# STM32H573 register map
File version: 1.7
CPU: CM33 r0p0, little endian, MPU, FPU, 4 interrupt priority bits
Registers are 32-bit, read-write, reset 0x0 unless marked. A register's access mark holds for its fields unless they carry their own. Offsets are from the block's base; [hi:lo] are bit positions; lines under a group give offsets from that group; {n}, {i} and the like mark numbered series; 'fields as' and 'values as' point back to an identical list.

## FLASH (part 2 of 2) — FLASH address block description
Base 0x40022000
Same registers: SEC_FLASH 0x50022000
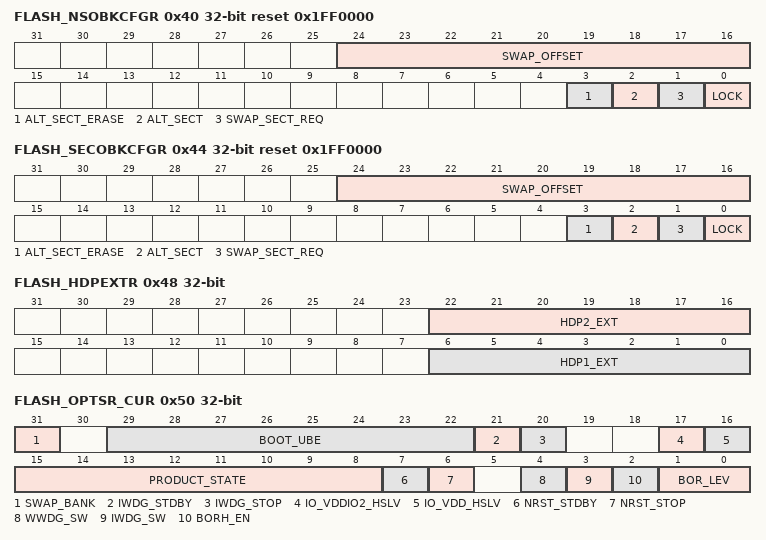
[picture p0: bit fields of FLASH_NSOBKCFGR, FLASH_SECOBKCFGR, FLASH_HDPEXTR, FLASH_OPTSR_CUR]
0x40 FLASH_NSOBKCFGR reset 0x1FF0000 — FLASH non-secure OBK configuration register
  [24:16] SWAP_OFFSET — Key index (offset /16 bits) pointing for next swap. 0x01 means that only the first OBK data (128 bits) is copied from current to alternate OBK sector 0x02 means that the two first OBK data is copied
    0=means that no OBK is copied from current to alternate OBK sector during SWAP operation; 0x1FF=means that all OBK data (511) is copied
  [3] ALT_SECT_ERASE — alternate sector erase bit When ALT_SECT bit is set, use this bit to generate an erase command for the OBK alternate sector. It is set only by Software and cleared when the OBK swap operation is completed or an error occurs (PGSERR). It is reseted at the same time as BUSY bit.
    0=do not touch OBK sector; 1=erase the alternate OBK sector
  [2] ALT_SECT — alternate sector bit This bit must not change while filling the write buffer, otherwise an error (OBKERR) is generated
    0=current OBK sector is mapped to OBK address range for access; 1=alternate OBK sector is mapped to OBK address range for access
  [1] SWAP_SECT_REQ — OBK swap sector request bit When set, all the OBKs which have not been updated in the alternate sector is copied from current sector to alternate one. The SWAP_OFFSET value must be a certain minimum value in order for the swap to be launched in OBK-HDPLdifferent 0. Minimum value is 16 for OBK-HDPL=1, 144 for OBK-HDPL=2 and192 for OBK-HDPL=3.
    0=no swap requested; 1=launch the sector swap
  [0] LOCK — OBKCFGR lock option configuration bit This bit locks the FLASH_NSOBKCFGR register. The correct write sequence to FLASH_NSOBKKEYR register unlocks this bit. If a wrong sequence is executed, or if the unlock sequence to FLASH_NSOBKKEYR is performed twice, this bit remains locked until the next system reset. LOCK can be set by programming it to 1. When set to 1, a new unlock sequence is mandatory to unlock it. When LOCK changes from 0 to 1, the other bits of FLASH_NSCR register do not change.
    0=FLASH_NSOBKCFGR register unlocked; 1=FLASH_NSOBKCFGR register locked
0x44 FLASH_SECOBKCFGR reset 0x1FF0000 — FLASH secure OBK configuration register
  [24:16] SWAP_OFFSET — key index (offset /16 bits) pointing for next swap.
    0=no OBK is copied from current to alternate OBK sector during SWAP operation; 1=only the first OBK data (128 bits) is copied from current to alternate OBK sector; 2=the two first OBK data are copied; 0x1FF=that the 511 first OBK data are copied
  [3] ALT_SECT_ERASE — alternate sector erase bit When ALT_SECT bit is set, use this bit to generate an erase command for the OBK alternate sector. It is set only by Software and cleared when the OBK swap operation is completed or an error occurs (PGSERR). It is reseted at the same time as the BUSY bit.
    0=do not touch OBK sector; 1=erase the alternate OBK sector
  [2] ALT_SECT — alternate sector bit This bit must not change while filling the write buffer, otherwise an error is generated
    values as FLASH_NSOBKCFGR.ALT_SECT
  [1] SWAP_SECT_REQ — OBK swap sector request bit When set, all the OBKs which have not been updated in the alternate sector is copied from current sector to alternate one. The SWAP_OFFSET value must be a certain minimum value in order for the swap to be launched in OBK-HDPLdifferent 0. Minimum value is 16 for OBK-HDPL=1, 144 for OBK-HDPL=2 and 192 for OBK-HDPL=3.
    0=no swap requested; 1=launch the sector swap
  [0] LOCK — OBKCFGR lock option configuration bit This bit locks the FLASH_OBKCFGR register. The correct write sequence to FLASH_SECOBKKEYR register unlocks this bit. If a wrong sequence is executed, or if the unlock sequence to FLASH_SECOBKKEYR is performed twice, this bit remains locked until the next system reset. LOCK can be set by programming it to 1. When set to 1, a new unlock sequence is mandatory to unlock it. When LOCK changes from 0 to 1, the other bits of FLASH_NSCR register do not change.
    0=FLASH_OBKCFGR register unlocked; 1=FLASH_OBKCFGR register locked
0x48 FLASH_HDPEXTR — FLASH HDP extension register
  [22:16] HDP2_EXT — HDP area extension in 8Kbytes sectors in bank 2. Extension is added after the HDP2_END sector (included).
  [6:0] HDP1_EXT — HDP area extension in 8Kbytes sectors in Bank1. Extension is added after the HDP1_END sector (included).
0x50 FLASH_OPTSR_CUR ro reset not defined — FLASH option status register
  [31] SWAP_BANK — Bank swapping option status bit SWAP_BANK reflects whether Bank1 and Bank2 are swapped or not. SWAP_BANK is loaded to SWAP_BANK of FLASH_OPTCR after a reset.
    0=Bank1 and Bank2 not swapped; 1=Bank1 and Bank2 swapped
  [29:22] BOOT_UBE — Available only on cryptography enabled devices. Unique boot entry control, selects either ST or OEM iRoT for secure boot.
    195=ST-iRoT (system flash) selected; 180=OEM-iRoT (user flash) selected. In Open PRODUCT_STATE this value selects bootloader. Defaut value.
  [21] IWDG_STDBY — IWDG Standby mode freeze option status bit When set the independent watchdog IWDG is frozen in system Standby mode.
    0=Independent watchdog frozen in Standby mode; 1=Independent watchdog keep running in Standby mode
  [20] IWDG_STOP — IWDG Stop mode freeze option status bit When set the independent watchdog IWDG is in system Stop mode.
    0=Independent watchdog frozen in system Stop mode; 1=Independent watchdog keep running in system Stop mode
  [17] IO_VDDIO2_HSLV — High-speed IO at low V sub DDIO2 /sub voltage configuration bit. This bit can be set only with V sub DDIO2 /sub below 2.7V.
    0=High-speed IO at low V sub DDIO2 /sub voltage feature disabled (V sub DDIO2 /sub can exceed 2.7V); 1=High-speed IO at low V sub DDIO2 /sub voltage feature enabled (V sub DDIO2 /sub remains below 2.7V)
  [16] IO_VDD_HSLV — High-speed IO at low V sub DD /sub voltage configuration bit. This bit can be set only with V sub DD /sub below 2.7V.
    0=High-speed IO at low V sub DD /sub voltage feature disabled (V sub DD /sub can exceed 2.7V); 1=High-speed IO at low V sub DD /sub voltage feature enabled (V sub DD /sub remains below 2.7V)
  [15:8] PRODUCT_STATE — Life state code (based on Hamming 8,4). More information in Section7.6.11: Product state transitions.
  [7] NRST_STDBY — Core domain Standby entry reset option status bit
    0=a reset is generated when entering Standby mode on core domain; 1=no reset generated when entering Standby mode on core domain
  [6] NRST_STOP — Core domain Stop entry reset option status bit
    0=a reset is generated when entering Stop mode on core domain; 1=no reset generated when entering Stop mode on core domain
  [4] WWDG_SW — WWDG control mode option status bit
    0=WWDG watchdog is controlled by hardware; 1=WWDG watchdog is controlled by software
  [3] IWDG_SW — IWDG control mode option status bit
    0=IWDG watchdog is controlled by hardware; 1=IWDG watchdog is controlled by software
  [2] BORH_EN — Brownout high enable
    0=disable; 1=enable
  [1:0] BOR_LEV — Brownout level option status bit These bits reflects the power level that generates a system reset. 00 or 11: BOR Level 1, the threshold level is low (around 2.1V)
    1=BOR Level 2, the threshold level is medium (around 2.4V); 2=BOR Level 3, the threshold level is high (around 2.7V)
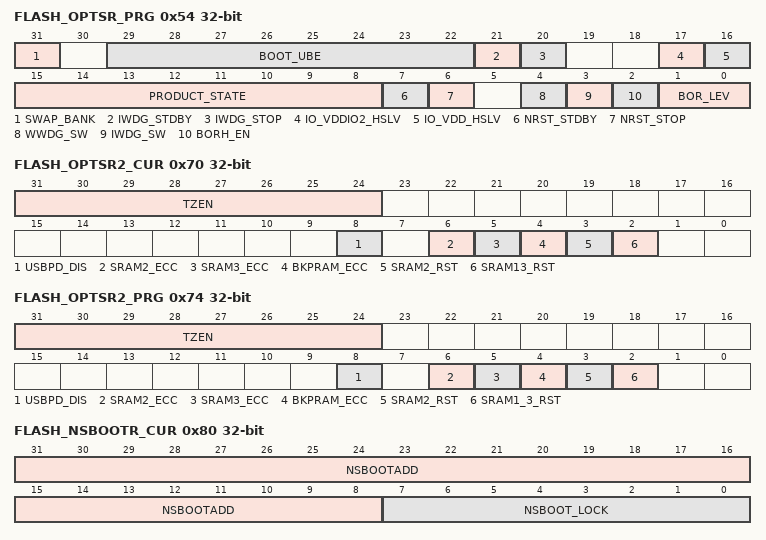
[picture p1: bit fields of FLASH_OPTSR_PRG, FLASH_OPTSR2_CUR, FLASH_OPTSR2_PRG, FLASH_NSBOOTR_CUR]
0x54 FLASH_OPTSR_PRG reset not defined — FLASH option status register
  [31] SWAP_BANK — Bank swapping option configuration bit SWAP_BANK option bit is used to configure whether the Bank1 and Bank2 are swapped or not. This bit is loaded with the SWAP_BANK bit of FLASH_OPTSR_CUR register after a reset.
    0=Bank1 and Bank2 not swapped; 1=Bank1 and Bank2 swapped
  [29:22] BOOT_UBE — Available only on cryptography enabled devices. Unique boot entry control, selects either ST or OEM iRoT for secure boot. In Open PRODUCT_STATE this value selects bootloader. Defaut value.
    195=ST-iRoT (system flash) selected; 180=OEM-iRoT (user flash) selected
  [21] IWDG_STDBY — IWDG Standby mode freeze option status bit When set the independent watchdog IWDG is frozen in system Standby mode.
    values as FLASH_OPTSR_CUR.IWDG_STDBY
  [20] IWDG_STOP — IWDG Stop mode freeze option status bit When set the independent watchdog IWDG is in system Stop mode.
    values as FLASH_OPTSR_CUR.IWDG_STOP
  [17] IO_VDDIO2_HSLV — High-speed IO at low VDDIO2 voltage configuration bit. This bit can be set only with VDDIO2 below 2.7V.
    0=High-speed IO at low VDDIO2 voltage feature disabled (VDDIO2 can exceed 2.7V); 1=High-speed IO at low VDDIO2 voltage feature enabled (VDDIO2 remains below 2.7V)
  [16] IO_VDD_HSLV — High-speed IO at low VDD voltage configuration bit. This bit can be set only with VDD below 2.7V.
    0=High-speed IO at low VDD voltage feature disabled (VDD can exceed 2.7V); 1=High-speed IO at low VDD voltage feature enabled (VDD remains below 2.7V)
  [15:8] PRODUCT_STATE — Life state code (based on Hamming 8,4). More information in Section7.6.11: Product state transitions.
  [7] NRST_STDBY — Core domain Standby entry reset option configuration bit
    values as FLASH_OPTSR_CUR.NRST_STDBY
  [6] NRST_STOP — Core domain Stop entry reset option configuration bit
    values as FLASH_OPTSR_CUR.NRST_STOP
  [4] WWDG_SW — WWDG control mode option configuration bit
    values as FLASH_OPTSR_CUR.WWDG_SW
  [3] IWDG_SW — IWDG control mode option configuration bit
    values as FLASH_OPTSR_CUR.IWDG_SW
  [2] BORH_EN — Brownout high enable configuration bit
    0=disable; 1=enable
  [1:0] BOR_LEV — Brownout level option configuration bit These bits reflects the power level that generates a system reset. 00 or 11: BOR Level 1, the threshold level is low (around 2.1 V)
    1=BOR Level 2, the threshold level is medium (around 2.4 V); 2=BOR Level 3, the threshold level is high (around 2.7 V)
0x60 FLASH_NSEPOCHR_CUR ro reset not defined — FLASH non-secure EPOCH register
  [23:0] NS_EPOCH — Non-volatile non-secure EPOCH counter
0x68 FLASH_SECEPOCHR_CUR ro reset not defined — FLASH secure EPOCH register
  [23:0] SEC_EPOCH — Non-volatile secure EPOCH counter
0x70 FLASH_OPTSR2_CUR ro reset not defined — FLASH option status register 2
  [31:24] TZEN — TrustZone enable configuration bits This bit enables the device is in TrustZone mode during an option byte change.
    195=TrustZone disabled; 180=TrustZone enabled
  [8] USBPD_DIS — USB power delivery configuration option bit
    0=Enabled; 1=Disabled
  [6] SRAM2_ECC — SRAM2 ECC detection and correction disable
    0=SRAM2 ECC check enabled; 1=SRAM2 ECC check disabled
  [5] SRAM3_ECC — SRAM3 ECC detection and correction disable
    0=SRAM3 ECC check enabled; 1=SRAM3 ECC check disabled
  [4] BKPRAM_ECC — Backup RAM ECC detection and correction disable
    0=BKPRAM ECC check enabled; 1=BKPRAM ECC check disabled
  [3] SRAM2_RST — SRAM2 erase when system reset
    0=SRAM2 erased when a system reset occurs; 1=SRAM2 not erased when a system reset occurs
  [2] SRAM13_RST — SRAM1 and SRAM3 erase upon system reset
    0=SRAM1 and SRAM3 erased when a system reset occurs; 1=SRAM1 and SRAM3 not erased when a system reset occurs
0x74 FLASH_OPTSR2_PRG reset not defined — FLASH option status register 2
  [31:24] TZEN — TrustZone enable configuration bits This bit enables the device is in TrustZone mode during an option byte change.
    195=TrustZone disabled; 180=TrustZone enabled
  [8] USBPD_DIS — USB power delivery configuration option bit
    0=Enabled; 1=Disabled
  [6] SRAM2_ECC — SRAM2 ECC detection and correction disable
    0=SRAM2 ECC check enabled; 1=SRAM2 ECC check disabled
  [5] SRAM3_ECC — SRAM3 ECC detection and correction disable
    0=SRAM3 ECC check enabled; 1=SRAM3 ECC check disabled
  [4] BKPRAM_ECC — Backup RAM ECC detection and correction disable
    0=BKPRAM ECC check enabled; 1=BKPRAM ECC check disabled
  [3] SRAM2_RST — SRAM2 erase when system reset Note: SRAM erase is triggered by option byte change operation, when enabling this feature.
    values as FLASH_OPTSR2_CUR.SRAM2_RST
  [2] SRAM1_3_RST — SRAM1 and SRAM3 erase upon system reset Note: SRAM erase is triggered by option byte change operation, when enabling this feature.
    values as FLASH_OPTSR2_CUR.SRAM13_RST
0x80 FLASH_NSBOOTR_CUR ro reset not defined — FLASH non-secure boot register
  [31:8] NSBOOTADD — Non secure unique boot entry address These bits reflect the Non secure UBE address
  [7:0] NSBOOT_LOCK — A field locking the values of SWAP_BANK, and NSBOOTADD settings.
    195=The SWAP_BANK and NSBOOTADD can still be modified following their individual rules; 180=The NSBOOTADD is frozen. SWAP_ BANK can only be modified with TZEN set to 0xB4 (enabled).
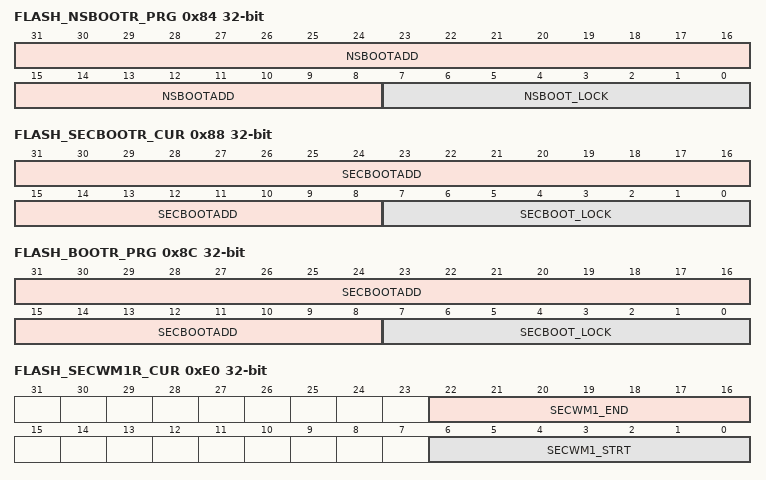
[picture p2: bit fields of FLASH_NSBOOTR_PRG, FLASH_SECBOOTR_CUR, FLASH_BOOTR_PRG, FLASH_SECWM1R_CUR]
0x84 FLASH_NSBOOTR_PRG reset not defined — FLASH non-secure boot register
  [31:8] NSBOOTADD — Non secure unique boot entry address These bits allow configuring the Non secure BOOT address
  [7:0] NSBOOT_LOCK — A field locking the values of SWAP_ BANK, and NSBOOTADD settings.
    195=The SWAP_ BANK and NSBOOTADD can still be modified following their individual rules; 180=The NSBOOTADD is frozen. SWAP_ BANK can only be modified with TZEN set to 0xB4 (enabled).
0x88 FLASH_SECBOOTR_CUR ro reset not defined — FLASH secure boot register
  [31:8] SECBOOTADD — Unique boot entry secure address These bits reflect the Secure UBE address
  [7:0] SECBOOT_LOCK — A field locking the values of UBE, SWAP_BANK, and SECBOOTADD settings.
    195=The BOOT_UBE, SWAP_BANK and SECBOOTADD can still be modified following their individual rules; 180=The BOOT_UBE and SECBOOTADD are frozen. SWAP_ BANK can only be modified with TZEN set to 0xC3 (disabled).
0x8C FLASH_BOOTR_PRG reset not defined — FLASH secure boot register
  [31:8] SECBOOTADD — Secure unique boot entry address. These bits allow configuring the secure UBE address.
  [7:0] SECBOOT_LOCK — A field locking the values of UBE, SWAP_ BANK, and SECBOOTADD setting.
    195=The BOOT_UBE, SWAP_ BANK and SECBOOTADD can still be modified following their individual rules; 180=The BOOT_UBE and SECBOOTADD are frozen. SWAP_BANK can only be modified with TZEN set to 0xC3 (disabled).
0x90 FLASH_OTPBLR_CUR ro reset not defined — FLASH non-secure OTP block lock
  [31:0] LOCKBL — OTP block lock Block n corresponds to OTP 16-bit word 32 x n to 32 x n + 31. LOCKBL[n] = 1 indicates that all OTP 16-bit words in OTP Block n are locked and attempt to program them results in WRPERR. LOCKBL[n] = 0 indicates that all OTP 16-bit words in OTP Block n are not locked. When one block is locked, it's not possible to remove the write protection. Also if not locked, it is not possible to erase OTP words.
0x94 FLASH_OTPBLR_PRG reset not defined — FLASH non-secure OTP block lock
  [31:0] LOCKBL — OTP block lock Block n corresponds to OTP 16-bit word 32 x n to 32 x n + 31. LOCKBL[n] = 1 indicates that all OTP 16-bit words in OTP Block n are locked and attempt to program them results in WRPERR. LOCKBL[n] = 0 indicates that all OTP 16-bit words in OTP Block n are not locked. When one block is locked, it is not possible to remove the write protection. LOCKBL bits can be set if the corresponding bit in FLASH_OTPBLR_CUR is cleared.
{0x9C+4i} FLASH_SECBB1R{i} (i=1..4) — FLASH secure block based register for Bank 1
  [31:0] SECBB1 — Secure/non-secure 8Kbytes flash Bank 1 sector attributes
    0=sector (32 * (x-1) + y) in bank 1 is non secure; 1=sector (32 * (x-1) + y) in bank 1 is secure
{0xBC+4i} FLASH_PRIVBB1R{i} (i=1..4) — FLASH privilege block based register for Bank 1
  [31:0] PRIVBB1 — Privileged/unprivileged 8-Kbyte flash Bank 1 sector attribute
    0=sectors (32 * (x-1) + y) in bank 1 is unprivileged; 1=sector (32 * (x-1) + y) in bank 1 is privileged
0xE0 FLASH_SECWM1R_CUR ro (reset mask 0xFF00FF00) — FLASH security watermark for Bank 1
  [22:16] SECWM1_END — Bank1 security WM area 1 end sector
  [6:0] SECWM1_STRT — Bank1 security WM area 1 start sector
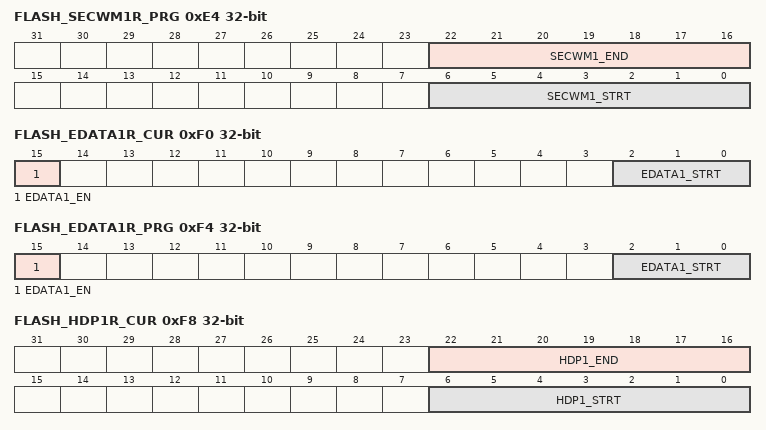
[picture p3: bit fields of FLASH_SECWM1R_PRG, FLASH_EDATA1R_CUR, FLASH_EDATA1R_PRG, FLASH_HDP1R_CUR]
0xE4 FLASH_SECWM1R_PRG (reset mask 0xFF00FF00) — FLASH security watermark for Bank 1
  fields as FLASH_SECWM1R_CUR
0xE8 FLASH_WRP1R_CUR ro reset not defined — FLASH write sector group protection for Bank 1
  [31:0] WRPSG1 — Bank 1 sector group protection option status byte Each FLASH_WRP1R_CUR bit reflects the write protection status of the corresponding group of four consecutive sectors in bank 1 (0: the group is write protected; 1: the group is not write protected) Bit 0: Group embedding sectors 0 to 3 Bit 1: Group embedding sectors 4 to 7 Bit N: Group embedding sectors 4 x N to 4 x N + 3 Bit 31: Group embedding sectors 124 to 127
0xEC FLASH_WRP1R_PRG reset not defined — FLASH write sector group protection for Bank 1
  [31:0] WRPSG1 — Bank1 sector group protection option status byte Setting WRPSG1 bits to 0 write protects the corresponding group of four consecutive sectors in bank 1 (0: the group is write protected; 1: the group is not write protected) Bit 0: Group embedding sectors 0 to 3 Bit 1: Group embedding sectors 4 to 7 Bit N: Group embedding sectors 4 x N to 4 x N + 3 Bit 31: Group embedding sectors 124 to 127
0xF0 FLASH_EDATA1R_CUR ro reset not defined — FLASH data sector configuration Bank 1
  [15] EDATA1_EN — Bank1 flash high-cycle data enable
    0=No flash high-cycle data area; 1=Flash high-cycle data is used
  [2:0] EDATA1_STRT — EDATA1_STRT contains the start sectors of the flash high-cycle data area in Bank1 There is no hardware effect to those bits. They shall be managed by ST tools in Flasher. ...
    0=The last sector of the Bank1 is reserved for flash high-cycle data; 1=The two last sectors of the Bank 1 are reserved for flash high-cycle data; 2=The three last sectors of the Bank 1 are reserved for flash high-cycle data; 7=The eight last sectors of the Bank 1 are reserved for flash high-cycle data
0xF4 FLASH_EDATA1R_PRG reset not defined — FLASH data sector configuration Bank 1
  [15] EDATA1_EN — Bank 1 flash high-cycle data enable
    values as FLASH_EDATA1R_CUR.EDATA1_EN
  [2:0] EDATA1_STRT — EDATA1_STRT contains the start sectors of the flash high-cycle data area in Bank 1 There is no hardware effect to those bits. They shall be managed by ST tools in Flasher. ... Note: 111: The eight last sectors of the Bank 1 are reserved for flash high-cycle data
    0=The last sector of the Bank 1 is reserved for flash high-cycle data; 1=The two last sectors of the Bank 1 are reserved for flash high-cycle data; 2=The three last sectors of the Bank 1 are reserved for flash high-cycle data
0xF8 FLASH_HDP1R_CUR ro reset not defined — FLASH HDP Bank 1 configuration
  [22:16] HDP1_END — HDPL barrier end set in number of 8-Kbyte sectors
  [6:0] HDP1_STRT — HDPL barrier start set in number of 8-Kbyte sectors
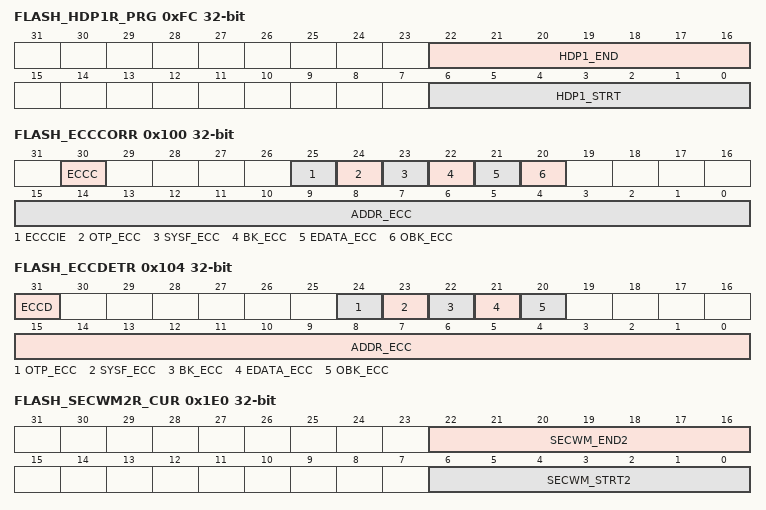
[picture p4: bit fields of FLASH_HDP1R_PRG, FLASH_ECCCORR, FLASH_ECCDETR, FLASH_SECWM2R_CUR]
0xFC FLASH_HDP1R_PRG reset not defined — FLASH HDP Bank 1 configuration
  fields as FLASH_HDP1R_CUR
0x100 FLASH_ECCCORR access per field — FLASH ECC correction register
  [30] ECCC rw — ECC correction set by hardware when single ECC error has been detected and corrected. Cleared by writing 1.
  [25] ECCCIE rw — ECC single correction error interrupt enable bit When ECCCIE bit is set to 1, an interrupt is generated when an ECC single correction error occurs during a read operation.
    0=no interrupt generated when an ECC single correction error occurs; 1=non-secure interrupt generated when an ECC single correction error occurs
  [24] OTP_ECC ro — OTP ECC error bit This bit is set to 1 when one single ECC correction occurred during the last successful read operation from the read-only/ OTP area. The address of the ECC error is available in ADDR_ECC bitfield.
  [23] SYSF_ECC ro — ECC fail for corrected ECC error in system flash memory It indicates if system flash memory is concerned by ECC error.
  [22] BK_ECC ro — ECC fail bank for corrected ECC error It indicates which bank is concerned by ECC error
  [21] EDATA_ECC ro — ECC fail for corrected ECC error in flash high-cycle data area It indicates if flash high-cycle data area is concerned by ECC error.
  [20] OBK_ECC ro — Single ECC error corrected in flash OB Keys storage area. It indicates the OBK storage concerned by ECC error.
  [15:0] ADDR_ECC ro — ECC error address When an ECC error occurs (for single correction) during a read operation, the ADDR_ECC contains the address that generated the error. ADDR_ECC is reset when the flag error is reset. The flash interface programs the address in this register only when no ECC error flags are set. This means that only the first address that generated an ECC error is saved. The address in ADDR_ECC is relative to the flash memory area where the error occurred (user flash memory, system flash memory, data area, read-only/OTP area).
0x104 FLASH_ECCDETR access per field — FLASH ECC detection register
  [31] ECCD rw — ECC detection Set by hardware when two ECC error has been detected. When this bit is set, a NMI is generated. Cleared by writing 1. Needs to be cleared in order to detect subsequent double ECC errors.
  [24] OTP_ECC ro — OTP ECC error bit This bit is set to 1 when double ECC detection occurred during the last read operation from the read-only/ OTP area. The address of the ECC error is available in ADDR_ECC bitfield.
  [23] SYSF_ECC ro — ECC fail for double ECC error in system flash memory It indicates if system flash memory is concerned by ECC error.
  [22] BK_ECC ro — ECC fail bank for double ECC error It indicates which bank is concerned by ECC error
  [21] EDATA_ECC ro — ECC fail double ECC error in flash high-cycle data area It indicates if flash high-cycle data area is concerned by ECC error.
  [20] OBK_ECC ro — ECC fail double ECC error in flash OB Keys storage area. It indicates the OBK storage concerned by ECC error.
  [15:0] ADDR_ECC ro — ECC error address When an ECC error occurs (double detection) during a read operation, the ADDR_ECC contains the address that generated the error. ADDR_ECC is reset when the flag error is reset. The flash interface programs the address in this register only when no ECC error flags are set. This means that only the first address that generated an double ECC error is saved. The address in ADDR_ECC is relative to the flash memory area where the error occurred (user flash memory, system flash memory, data area, read-only/OTP area).
0x108 FLASH_ECCDR ro — FLASH ECC data
  [15:0] DATA_ECC — ECC error data When an double detection ECC error occurs on special areas with 6-bit ECC on 16-bit data (data area, read-only/OTP area), the failing data is read to this register. By checking if it is possible to determine whether the failure was on a real data, or due to access to uninitialized memory.
{0x19C+4i} FLASH_SECBB2R{i} (i=1..4) — FLASH secure block-based register for Bank 2
  [31:0] SECBB2 — Secure/non-secure flash Bank 2 sector attribute
    0=sectors (32 * (x-1) + y) in bank 2 is non secure; 1=sector (32 * (x-1) + y) in bank 2 is secure
{0x1BC+4i} FLASH_PRIVBB2R{i} (i=1..4) — FLASH privilege block-based register for Bank 2
  [31:0] PRIVBB2 — Privileged / non-privileged 8-Kbyte flash Bank 2 sector attribute
    0=sectors (32 * (x-1) + y) in bank 2 is unprivileged; 1=sector (32 * (x-1) + y) in bank 2 is privileged
0x1E0 FLASH_SECWM2R_CUR ro (reset mask 0xFF00FF00) — FLASH security watermark for Bank 2
  [22:16] SECWM_END2 — Bank2 security WM end sector
  [6:0] SECWM_STRT2 — Bank2 security WM area start sector
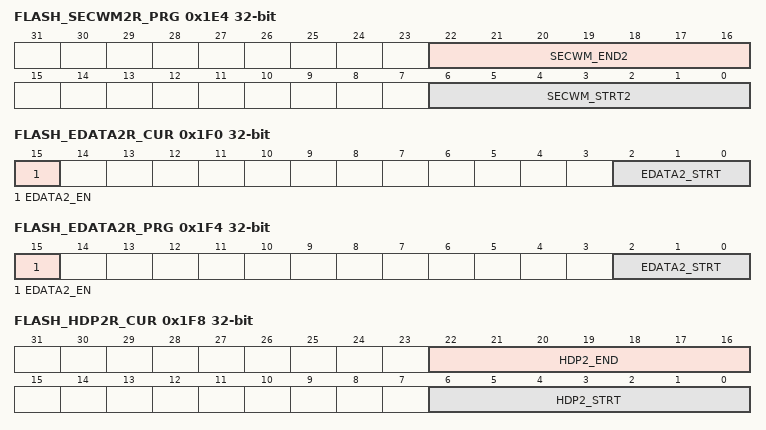
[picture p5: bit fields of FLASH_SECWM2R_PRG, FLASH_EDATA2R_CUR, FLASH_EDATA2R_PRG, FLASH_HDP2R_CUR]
0x1E4 FLASH_SECWM2R_PRG (reset mask 0xFF00FF00) — FLASH security watermark for Bank 2
  [22:16] SECWM_END2 — Bank 2 security WM area end sector
  [6:0] SECWM_STRT2 — Bank 2 security WM area start sector
0x1E8 FLASH_WRP2R_CUR ro reset not defined — FLASH write sector group protection for Bank 2
  [31:0] WRPSG2 — Bank2 sector group protection option status byte Each FLASH_WRP2R_CUR bit reflects the write protection status of the corresponding group of 4 consecutive sectors in bank 2 (0: group is write protected; 1: group is not write protected) Bit 0: Group embedding sectors 0 to 3 Bit 1: Group embedding sectors 4 to 7 Bit N: Group embedding sectors 4 x N to 4 x N + 3 Bit 31: Group embedding sectors 124 to 127
0x1EC FLASH_WRP2R_PRG reset not defined — FLASH write sector group protection for Bank 2
  [31:0] WRPSG2 — Bank 2 sector group protection option status byte Setting WRPSGn2 bits to 0 write protects the corresponding group of four consecutive sectors in Bank 2 (0: group is write protected; 1: group is not write protected) Bit 0: Group embedding sectors 0 to 3 Bit 1: Group embedding sectors 4 to 7 Bit N: Group embedding sectors 4 x N to 4 x N + 3 Bit 31: Group embedding sectors 124 to 127
0x1F0 FLASH_EDATA2R_CUR ro reset not defined — FLASH data sectors configuration Bank 2
  [15] EDATA2_EN — Bank2 flash high-cycle data enable
    values as FLASH_EDATA1R_CUR.EDATA1_EN
  [2:0] EDATA2_STRT — EDATA2_STRT contains the start sectors of the flash high-cycle data area in Bank 2 There is no hardware effect to those bits. They shall be managed by ST tools in Flasher. ... Note: 111: The eight last sectors of the Bank 2 are reserved for flash high-cycle data
    0=The last sector of the bank 2is reserved for flash high-cycle data; 1=The two last sectors of the Bank 2 are reserved for flash high-cycle data; 2=The three last sectors of the Bank 2 are reserved for flash high-cycle data
0x1F4 FLASH_EDATA2R_PRG reset not defined — FLASH data sector configuration Bank 2
  [15] EDATA2_EN — Bank 2 flash high-cycle data enable
    values as FLASH_EDATA1R_CUR.EDATA1_EN
  [2:0] EDATA2_STRT — EDATA2_STRT contains the start sectors of the flash high-cycle data area in Bank 2 There is no hardware effect to those bits. They shall be managed by ST tools in Flasher. ... Note: 111: The eight last sectors of the Bank 2 are reserved for flash high-cycle data.
    0=The last sector of the Bank 2 is reserved for flash high-cycle data; 1=The two last sectors of the Bank 2 are reserved for flash high-cycle data; 2=The three last sectors of the Bank 2 are reserved for flash high-cycle data
0x1F8 FLASH_HDP2R_CUR ro reset not defined — FLASH HDP Bank 2 configuration
  [22:16] HDP2_END — HDPL barrier end set in number of 8-Kbyte sectors
  [6:0] HDP2_STRT — HDPL barrier start set in number of 8-Kbyte sectors
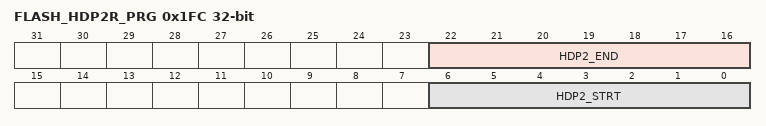
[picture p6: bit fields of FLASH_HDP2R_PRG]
0x1FC FLASH_HDP2R_PRG reset not defined — FLASH HDP Bank 2 configuration
  fields as FLASH_HDP2R_CUR
